# S32R372 register map
Vendor: Freescale Semiconductor, Inc.; Series: Qorivva; File version: 1.6
Registers are 32-bit, read-write, reset 0x0 unless marked. A register's access mark holds for its fields unless they carry their own. Offsets are from the block's base; [hi:lo] are bit positions; {n}, {i} and the like mark numbered series; 'fields as' and 'values as' point back to an identical list.

## FlexPWM_0 — FlexPWM
Base 0xFBC00000; register names take the prefix FlexPWM_0_
{0x0+0x50*i} SUB{i}_CNT (i=0..3) 16-bit ro — Submodule n Counter Register
  [15:0] CNT — Count
{0x2+0x50*i} SUB{i}_INIT (i=0..3) 16-bit — Submodule n Initial Count Register
  [15:0] INIT — Initial count
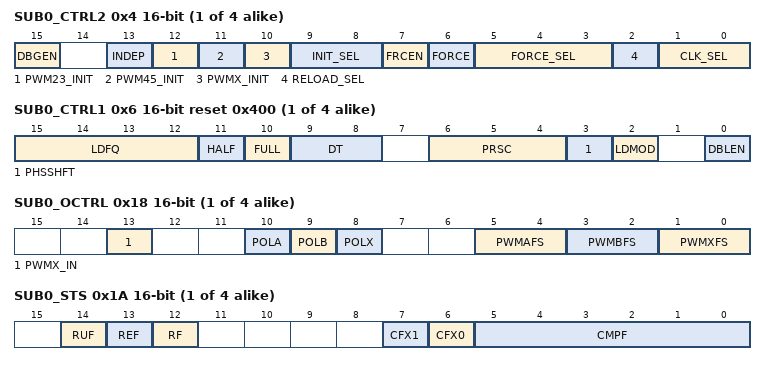
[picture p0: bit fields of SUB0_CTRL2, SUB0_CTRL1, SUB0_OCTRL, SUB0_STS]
{0x4+0x50*i} SUB{i}_CTRL2 (i=0..3) 16-bit — Submodule n Control 2 Register
  [15] DBGEN — Debug Enable
  [13] INDEP — Independent or Complementary Pair Operation
    0=PWMA and PWMB form a complementary PWM pair; 1=PWMA and PWMB outputs are independent PWMs
  [12] PWM23_INIT — PWM23 Initial Value
  [11] PWM45_INIT — PWM45 Initial Value
  [10] PWMX_INIT — PWMX Initial Value
  [9:8] INIT_SEL — Initialization Control Select
    0=Local sync (PWMX) causes initialization; 1=Master reload from submodule 0 causes initialization. This setting should not be used in submodule 0 as it will force the INIT signal to logic 0.; 2=Master sync from submodule 0 causes initialization. This setting should not be used in submodule 0 as it will force the INIT signal to logic 0.; 3=EXT_SYNC causes initialization
  [7] FRCEN — Force Initialization Enable
    0=Initialization from a Force Out event is disabled; 1=Initialization from a Force Out event is enabled
  [6] FORCE wo — Force Initialization
  [5:3] FORCE_SEL — Force Source Select
    0=The local force signal, FORCE, from this submodule is used to force updates; 1=The master force signal from submodule 0 is used to force updates. This setting should not be used in submodule 0 as it will hold the FORCE OUTPUT signal to logic 0.; 2=The local reload signal from this submodule is used to force updates without regard to the state of LDOK; 3=The master reload signal from submodule0 is used to force updates if LDOK is set. This setting should not be used in submodule0 as it will hold the FORCE OUTPUT signal to logic 0.; 4=The local sync signal from this submodule is used to force updates; 5=The master sync signal from submodule0 is used to force updates. This setting should not be used in submodule0 as it will hold the FORCE OUTPUT signal to logic 0.; 6=The external force signal, EXT_FORCE, from outside the PWM module causes updates
  [2] RELOAD_SEL — Reload Source Select
    0=The local RELOAD signal is used to reload registers; 1=The master RELOAD signal (from submodule 0) is used to reload registers. This setting should not be used in submodule 0 as it will force the RELOAD signal to logic 0.
  [1:0] CLK_SEL — Clock Source Select
    0=The peripheral clock is used as the clock for the local prescaler and counter; 1=EXT_CLK is used as the clock for the local prescaler and counter; 2=Submodule 0's clock (AUX_CLK) is used as the source clock for the local prescaler and counter. This setting should not be used in submodule 0 as it will force the clock to logic 0.
{0x6+0x50*i} SUB{i}_CTRL1 (i=0..3) 16-bit reset 0x400 — Submodule n Control 1 Register
  [15:12] LDFQ — Load Frequency
  [11] HALF — Half Cycle Reload
    0=Half-cycle reloads disabled; 1=Half-cycle reloads enabled
  [10] FULL — Full Cycle Reload
    0=Full-cycle reloads disabled; 1=Full-cycle reloads enabled
  [9:8] DT ro — Deadtime
  [6:4] PRSC — Prescaler
    0=PWM clock frequency = f CLK; 1=PWM clock frequency = f CLK / 2; 2=PWM clock frequency = f CLK / 4; 3=PWM clock frequency = f CLK / 8; 4=PWM clock frequency = f CLK / 16; 5=PWM clock frequency = f CLK / 32; 6=PWM clock frequency = f CLK / 64; 7=PWM clock frequency = f CLK / 128
  [3] PHSSHFT — Phase Shift Mode Enable
    0=Phase shifted mode is disabled. The EXT_SWITCH input is ignored. Normal operation.; 1=Phase shifted mode is enabled. The EXT_SWITCH input is used to select generated PWM source for force out logic in submodule 0.
  [2] LDMOD — Load Mode Select
    0=Buffered registers of this submodule are loaded and take effect at the next PWM reload if LDOK is set; 1=Buffered registers of this submodule are loaded and take effect immediately upon LDOK being set
  [0] DBLEN — Double Switching Enable
    0=Double switching disabled; 1=Double switching enabled
{0x8+0x50*i} SUB{i}_VAL0 (i=0..3) 16-bit — Submodule n Value Register 0
  [15:0] VAL0 — Value 0
{0xA+0x50*i} SUB{i}_VAL1 (i=0..3) 16-bit — Submodule n Value Register 1
  [15:0] VAL1 — Value 1
{0xC+0x50*i} SUB{i}_VAL2 (i=0..3) 16-bit — Submodule n Value Register 2
  [15:0] VAL2 — Value 2
{0xE+0x50*i} SUB{i}_VAL3 (i=0..3) 16-bit — Submodule n Value Register 3
  [15:0] VAL3 — Value 3
{0x10+0x50*i} SUB{i}_VAL4 (i=0..3) 16-bit — Submodule n Value Register 4
  [15:0] VAL4 — Count value to set PWM45 high
{0x12+0x50*i} SUB{i}_VAL5 (i=0..3) 16-bit — Submodule n Value Register 5
  [15:0] VAL5 — Count value to set PWM45 low
{0x18+0x50*i} SUB{i}_OCTRL (i=0..3) 16-bit — Submodule n Output Control Register
  [13] PWMX_IN ro — PWMX Input This read only bit shows the logic value currently being driven into the PWMX input.
  [10] POLA — PWMA Output Polarity This bit inverts the PWMA output polarity.
    0=PWMA output not inverted. A high level on the PWMA pin represents the "on" or "active" state.; 1=PWMA output inverted. A low level on the PWMA pin represents the "on" or "active" state.
  [9] POLB — PWMB Output Polarity This bit inverts the PWMB output polarity.
    0=PWMB output not inverted. A high level on the PWMB pin represents the "on" or "active" state.; 1=PWMB output inverted. A low level on the PWMB pin represents the "on" or "active" state.
  [8] POLX — PWMX Output Polarity This bit inverts the PWMX output polarity.
    0=PWMX output not inverted. A high level on the PWMX pin represents the "on" or "active" state.; 1=PWMX output inverted. A low level on the PWMX pin represents the "on" or "active" state.
  [5:4] PWMAFS — PWMA Fault State
    0=Output is forced to logic 0 state prior to consideration of output polarity control; 1=Output is forced to logic 1 state prior to consideration of output polarity control; 2=Output is tristated; 3=Output is tristated
  [3:2] PWMBFS — PWMB Fault State
    values as PWMAFS
  [1:0] PWMXFS — PWMX Fault State
    values as PWMAFS
{0x1A+0x50*i} SUB{i}_STS (i=0..3) 16-bit — Submodule n Status Register
  [14] RUF ro — Registers Updated Flag This read-only flag is set when SUBn_INIT, SUBn_VALx, or SUBn_CTRL1[PRSC] has been written resulting in non-coherent data in the set of double-buffered registers
    0=No register update has occurred since last reload; 1=At least one of the double buffered registers has been updated since the last reload
  [13] REF — Reload Error Flag This read/write flag is set when a reload cycle occurs while LDOK is 0 and the double buffered registers are in a non-coherent state (RUF = 1)
    0=No reload error occurred; 1=Reload signal occurred with non-coherent data and LDOK = 0
  [12] RF — Reload Flag This read/write flag is set at the beginning of every reload cycle regardless of the state of the LDOK bit
    0=No new reload cycle since last RF clearing; 1=New reload cycle since last RF clearing
  [7] CFX1 — Capture Flag X1 This bit is set when the word count of the Capture X1 FIFO (CX1CNT) exceeds the value of the CFXWM field
  [6] CFX0 — Capture Flag X0 This bit is set when the word count of the Capture X0 FIFO (CX0CNT) exceeds the value of the CFXWM field
  [5:0] CMPF — Compare Flags These bits are set when the submodule counter value matches the value of one of the SUBn_VALx registers
    0=No compare event has occurred for a particular VALx value; 1=A compare event has occurred for a particular VALx value
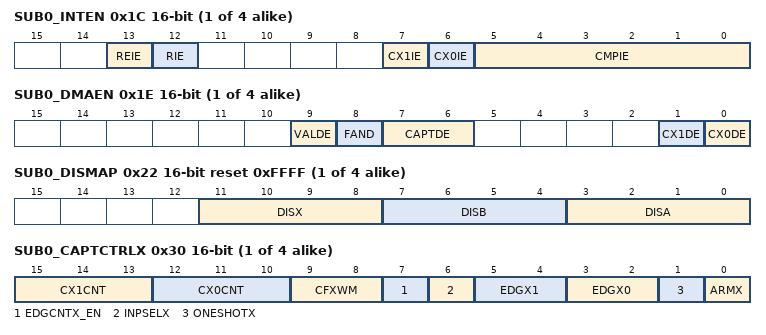
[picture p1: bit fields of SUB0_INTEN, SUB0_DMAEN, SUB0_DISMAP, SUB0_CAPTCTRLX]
{0x1C+0x50*i} SUB{i}_INTEN (i=0..3) 16-bit — Submodule n Interrupt Enable Register
  [13] REIE — Reload Error Interrupt Enable This read/write bit enables the reload error flag (REF) to generate CPU interrupt requests
    0=REF CPU interrupt requests disabled; 1=REF CPU interrupt requests enabled
  [12] RIE — Reload Interrupt Enable This read/write bit enables the reload flag (RF) to generate CPU interrupt requests
    0=RF CPU interrupt requests disabled; 1=RF CPU interrupt requests enabled
  [7] CX1IE — Capture X 1 Interrupt Enable This bit allows the CFX1 flag to create an interrupt request to the CPU
    0=Interrupt request disabled for CFX1; 1=Interrupt request enabled for CFX1
  [6] CX0IE — Capture X 0 Interrupt Enable This bit allows the CFX0 flag to create an interrupt request to the CPU
    0=Interrupt request disabled for CFX0; 1=Interrupt request enabled for CFX0
  [5:0] CMPIE — Compare Interrupt Enables These bits enable the CMPF flags to cause a compare interrupt request to the CPU
    0=The corresponding CMPF bit will not cause an interrupt request; 1=The corresponding CMPF bit will cause an interrupt request
{0x1E+0x50*i} SUB{i}_DMAEN (i=0..3) 16-bit — Submodule n DMA Enable Register
  [9] VALDE — Value Registers DMA Enable This read/write bit enables DMA write requests for the SUBn_VALx registers when RF is set
    0=DMA write requests disabled; 1=DMA write requests for the SUBn_VALx registers enabled
  [8] FAND — FIFO Watermark AND Control This read/write bit works in conjunction with the CAPTDE field when it is set to watermark mode (CAPTDE = 01)
    0=Selected FIFO watermarks are OR'ed together; 1=Selected FIFO watermarks are AND'ed together
  [7:6] CAPTDE — Capture DMA Enable Source Select These read/write bits select the source of enabling the DMA read requests for the capture FIFOs
    0=Read DMA requests disabled; 1=Exceeding a FIFO watermark sets the DMA read request. This requires at least 1 of the CA1DE, CA0DE, CB1DE, CB0DE, CX1DE, or CX0DE bits to also be set in order to determine which watermark(s) the DMA request is sensitive to.; 2=A local sync (VAL1 matches counter) sets the read DMA request; 3=A local reload (RF being set) sets the read DMA request
  [1] CX1DE — Capture X1 FIFO DMA Enable This read/write bit enables DMA read requests for the Capture X1 FIFO data when CFX1 is set
  [0] CX0DE — Capture X0 FIFO DMA Enable This read/write bit enables DMA read requests for the Capture X0 FIFO data when CFX0 is set
{0x20+0x50*i} SUB{i}_TCTRL (i=0..3) 16-bit — Submodule n Output Trigger Control Register
  [5:0] OUT_TRIG_EN — Output Trigger Enables These bits enable the generation of OUT_TRIG0 and OUT_TRIG1 outputs based on the counter value matching the value in one or more of the SUBn_VALx registers
    0=OUT_TRIGx will not set when the counter value matches the VALx value; 1=OUT_TRIGx will set when the counter value matches the VALx value
{0x22+0x50*i} SUB{i}_DISMAP (i=0..3) 16-bit reset 0xFFFF — Submodule n Fault Disable Mapping Register
  [11:8] DISX — PWMX Fault Disable Mask Each of the four bit of this read/write field is one-to-one associated with the four FAULTx inputs
  [7:4] DISB — PWMB Fault Disable Mask Each of the four bit of this read/write field is one-to-one associated with the four FAULTx inputs
  [3:0] DISA — PWMA Fault Disable Mask Each of the four bit of this read/write field is one-to-one associated with the four FAULTx inputs
{0x24+0x50*i} SUB{i}_DTCNT0 (i=0..3) 16-bit reset 0x7FF — Submodule n Deadtime Count Register 0
  [10:0] DTCNT0 — Controls the deadtime during 0 to 1 transitions of the PWMA output (assuming normal polarity) in terms of clock cycles regardless of the setting of PRSC and/or CLK_SEL
{0x26+0x50*i} SUB{i}_DTCNT1 (i=0..3) 16-bit reset 0x7FF — Submodule n Deadtime Count Register 1
  [10:0] DTCNT1 — Controls the deadtime during 0 to 1 transitions of the complementary PWMB output, in terms of clock cycles regardless of the setting of PRSC and/or CLK_SEL
{0x30+0x50*i} SUB{i}_CAPTCTRLX (i=0..3) 16-bit — Submodule n Capture Control X Register
  [15:13] CX1CNT ro — Capture X1 FIFO Word Count This field reflects the number of words in the Capture X1 FIFO.
  [12:10] CX0CNT ro — Capture X0 FIFO Word Count This field reflects the number of words in the Capture X0 FIFO.
  [9:8] CFXWM — Capture X FIFOs Watermark
  [7] EDGCNTX_EN — Edge Counter X Enable This bit enables the edge counter which counts rising and falling edges on the PWMX input signal
    0=Edge counter disabled and held in reset; 1=Edge counter enabled
  [6] INPSELX — Input Select X This bit selects between the raw PWMX input signal and the output of the edge counter/compare circuitry as the source for the input capture circuit
    0=Raw PWMX input signal selected as source; 1=Output of edge counter/compare selected as source
  [5:4] EDGX1 — Edge X 1 These bits control the input capture 1 circuitry by determining which input edges cause a capture event
    0=Disabled; 1=Capture falling edges; 2=Capture rising edges; 3=Capture any edge
  [3:2] EDGX0 — Edge X 0 These bits control the input capture 0 circuitry by determining which input edges cause a capture event
    values as EDGX1
  [1] ONESHOTX — One Shot Mode Aux This bit selects between free running and one shot mode for the input capture circuitry
    0=Free running mode is selected If both capture circuits are enabled, then capture circuit 0 is armed first after the ARMX bit is set. Once a capture occurs, capture circuit 0 is disarmed and capture circuit 1 is armed. After capture circuit 1 performs a capture, it is disarmed and capture circuit 0 is re-armed. The process continues indefinitely. If only one of the capture circuits is enabled, then captures continue indefinitely on the enabled capture circuit.; 1=One shot mode is selected. If both capture circuits are enabled, then capture circuit 0 is armed first after the ARMX bit is set. Once a capture occurs, capture circuit 0 is disarmed and capture circuit 1 is armed. After capture circuit 1 performs a capture, it is disarmed and the ARMX bit is cleared. No further captures will be performed until the ARMX bit is set again. If only one of the capture circuits is enabled, then a single capture will occur on the enabled capture circuit and the ARMX bit is then cleared.
  [0] ARMX — Arm X Setting this bit high starts the input capture process
    0=Input capture operation is disabled; 1=Input capture operation as specified by the EDGX bits is enabled
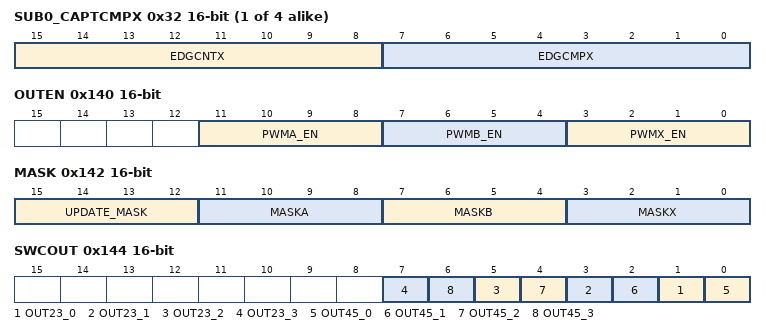
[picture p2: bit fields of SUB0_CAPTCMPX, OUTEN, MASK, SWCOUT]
{0x32+0x50*i} SUB{i}_CAPTCMPX (i=0..3) 16-bit — Submodule n Capture Compare X Register
  [15:8] EDGCNTX ro — Edge Counter X This read only field contains the edge counter value for the PWMX input capture circuitry
  [7:0] EDGCMPX — Edge Compare X This read/write field is the compare value associated with the edge counter for the PWMX input capture circuitry
{0x34+0x50*i} SUB{i}_CVAL0 (i=0..3) 16-bit ro — Submodule n Capture Value 0 Register
  [15:0] CAPTVAL0 — Value captured from the submodule counter
{0x36+0x50*i} SUB{i}_CVAL0CYC (i=0..3) 16-bit ro — Submodule n Capture Value 0 Cycle Register
  [2:0] CVAL0CYC — CVAL0 Cycle
{0x38+0x50*i} SUB{i}_CVAL1 (i=0..3) 16-bit ro — Submodule n Capture Value 1 Register
  [15:0] CAPTVAL1 — Value captured from the submodule counter
{0x3A+0x50*i} SUB{i}_CVAL1CYC (i=0..3) 16-bit ro — Submodule n Capture Value 1 Cycle Register
  [2:0] CVAL1CYC — CVAL1 Cycle
0x140 OUTEN 16-bit — Output Enable Register
  [11:8] PWMA_EN — PWMA Output Enables These bits enable the PWMA outputs of each submodule
    0=PWMA output disabled; 1=PWMA output enabled
  [7:4] PWMB_EN — PWMB Output Enables These bits enable the PWMB outputs of each submodule
    0=PWMB output disabled; 1=PWMB output enabled
  [3:0] PWMX_EN — PWMX Output Enables These bits enable the PWMX outputs of each submodule
    0=PWMX output disabled; 1=PWMX output enabled
0x142 MASK 16-bit
  [15:12] UPDATE_MASK wo
    0=Normal operation. MASK* bits within the submodules aren't updated until a FORCE_OUT event occurs within the submodule.; 1=Immediate operation. MASK* bits within the corresponding submodules are updated on the following clock edge after setting this bit.
  [11:8] MASKA — PWMA Masks These bits mask the PWMA outputs of each submodule forcing the output to logic 0 prior to consideration of the output polarity
    0=PWMA output normal; 1=PWMA output masked
  [7:4] MASKB — PWMB Masks These bits mask the PWMB outputs of each submodule forcing the output to logic 0 prior to consideration of the output polarity
    0=PWMB output normal; 1=PWMB output masked
  [3:0] MASKX — PWMX Masks These bits mask the PWMX outputs of each submodule forcing the output to logic 0 prior to consideration of the output polarity
    0=PWMX output normal; 1=PWMX output masked
0x144 SWCOUT 16-bit — Software Controlled Output Register
  [2n+1] OUT23_{n} (n=0..3) — Software Controlled Output 23_{n} This bit is only used when SEL23 for submodule {n} is set to 0b10
    0=A logic 0 is supplied to the deadtime generator of submodule {n} instead of PWM23; 1=A logic 1 is supplied to the deadtime generator of submodule {n} instead of PWM23
  [2n] OUT45_{n} (n=0..3) — Software Controlled Output 45_{n} This bit is only used when SEL45 for submodule {n} is set to 0b10
    0=A logic 0 is supplied to the deadtime generator of submodule {n} instead of PWM45; 1=A logic 1 is supplied to the deadtime generator of submodule {n} instead of PWM45
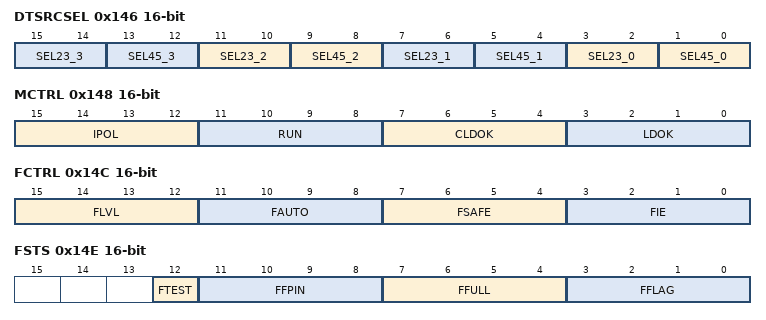
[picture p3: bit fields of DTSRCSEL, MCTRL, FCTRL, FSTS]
0x146 DTSRCSEL 16-bit — Deadtime Source Select Register
  [4n+3:4n+2] SEL23_{n} (n=0..3) — PWM23_{n} Control Select This field selects possible over-rides to the generated PWM23 signal in submodule {n} that will be passed to the deadtime logic upon the occurrence of a "Force Out" event in that submodule
    0=Generated PWM23_{n} signal is used by the deadtime logic; 1=Inverted generated PWM23_{n} signal is used by the deadtime logic; 2=OUT23_{n} bit is used by the deadtime logic; 3=EXTA[{n}] signal is used by the deadtime logic
  [4n+1:4n] SEL45_{n} (n=0..3) — PWM45_{n} Control Select This field selects possible over-rides to the generated PWM45 signal in submodule {n} that will be passed to the deadtime logic upon the occurrence of a "Force Out" event in that submodule
    0=Generated PWM45_{n} signal is used by the deadtime logic; 1=Inverted generated PWM45_{n} signal is used by the deadtime logic; 2=OUT45_{n} bit is used by the deadtime logic; 3=EXTB[{n}] signal is used by the deadtime logic
0x148 MCTRL 16-bit — Master Control Register
  [15:12] IPOL — Current Polarity
    0=PWM23 ( PWM submodule ) is used to generate complementary PWM pair; 1=PWM45 ( PWM submodule ) is used to generate complementary PWM pair
  [11:8] RUN
    0=PWM generator disabled; 1=PWM generator enabled
  [7:4] CLDOK wo — Clear Load Okay
  [3:0] LDOK — Load Okay
    0=Do not load new values; 1=Load prescaler, modulus, and PWM values
0x14C FCTRL 16-bit — Fault Control Register
  [15:12] FLVL — Fault Level These read/write bits select the active logic level of the individual fault inputs
    0=A logic 0 on the fault input indicates a fault condition; 1=A logic 1 on the fault input indicates a fault condition
  [11:8] FAUTO — Automatic Fault Clearing These read/write bits select automatic or manual clearing of faults
    0=Manual fault clearing. PWM outputs disabled by this fault are not enabled until the FFLAGx bit is clear at the start of a half cycle or full cycle depending the state of the FFULL bits. This is further controlled by the FSAFE bits.; 1=Automatic fault clearing. PWM outputs disabled by this fault are enabled when the FFPINx bit is clear at the start of a half cycle or full cycle depending on the state of the FFULL bits without regard to the state of FFLAGx bit.
  [7:4] FSAFE — Fail Safe Mode These read/write bits select the safety mode during manual fault clearing
    0=Normal mode. PWM outputs disabled by this fault are not enabled until the FFLAGx bit is clear at the start of a half cycle or full cycle depending on the state of the FFULL bits without regard to the state of the FFPINx bit. The PWM outputs disabled by this fault input will not be re-enabled until the actual FAULTx input signal de-asserts. This is because the fault inputs have a direct combinational link to disable the PWM outputs (as programmed in DISMAP).; 1=Safe mode. PWM outputs disabled by this fault are not enabled until the FFLAGx bit is clear and the FFPINx bit is clear at the start of a half cycle or full cycle depending on the state of the FFULL bits.
  [3:0] FIE — Fault Interrupt Enables This read/write bit enables CPU interrupt requests generated by the FAULTx pins
    0=FAULTx CPU interrupt requests disabled; 1=FAULTx CPU interrupt requests enabled
0x14E FSTS 16-bit — Fault Status Register
  [12] FTEST — Fault Test These read/write bit is used to simulate a fault condition
    0=No fault; 1=Cause a simulated fault
  [11:8] FFPIN ro — Filtered Fault Pins These read-only bits reflect the current state of the filtered FAULTx pins converted to high polarity
  [7:4] FFULL — Full Cycle These read/write bits are used to control the timing for re-enabling the PWM outputs after a fault condition
    0=PWM outputs are re-enabled at the start of a full or half cycle; 1=PWM outputs are re-enabled only at the start of a full cycle
  [3:0] FFLAG — Fault Flags These read-only flags are set in either the fourth or fifth cycle (depending on clock synchronisation) of the FlexPWM clock, after a transition to active on the FAULTx pin
    0=No fault on the FAULTx pin; 1=Fault on the FAULTx pin
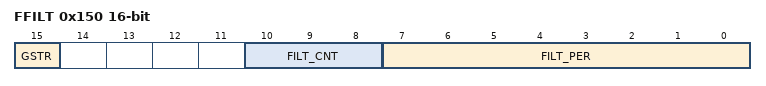
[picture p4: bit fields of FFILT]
0x150 FFILT 16-bit — Fault Filter Register
  [15] GSTR — Fault Glitch Stretch Enable This bit is used to enable the fault glitch stretching logic
    0=Fault input glitch stretching is disabled; 1=Input fault signals will be stretched to at least 2 peripheral clock cycles
  [10:8] FILT_CNT — Fault Filter Count These bits represent the number of consecutive samples that must agree prior to the input filter accepting an input transition
  [7:0] FILT_PER — Fault Filter Period These bits represent the sampling period (in peripheral clock cycles) of the fault pin input filter
0x152 FCTRL2 16-bit — Fault Control 2 Register
  [3:0] NOCOMB — No combinational path from fault inputs to PWM outputs
    0=There is a combinational link from the fault inputs to the PWM outputs. The fault inputs are combined with the filtered and latched fault signals to disable the PWM outputs.; 1=The direct combinational path from the fault inputs to the PWM outputs is disabled and the filtered and latched fault signals are used to disable the PWM outputs
